# CY8C5888LTI_LP097 register map
File version: 0.1
Registers are 8-bit, read-write, no defined reset value unless marked. A register's access mark holds for its fields unless they carry their own. Offsets are from the block's base; [hi:lo] are bit positions; 'fields as' and 'values as' point back to an identical list.

## PWM_1
Base 0x00000000
0x4000642A PWM_1_COMPARE_Reg 16-bit — UDB.D0 - Assigned Compare Value
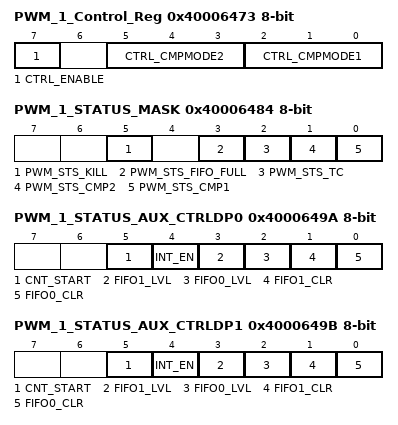
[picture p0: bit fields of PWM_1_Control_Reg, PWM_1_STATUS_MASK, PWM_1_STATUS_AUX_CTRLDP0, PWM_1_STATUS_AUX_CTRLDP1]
0x40006473 PWM_1_Control_Reg — UDB Control Register - Assigned Control Register Value
  [7] CTRL_ENABLE — Enable the PWM
  [5:3] CTRL_CMPMODE2 — Compare mode 2
  [2:0] CTRL_CMPMODE1 — Compare mode 1
0x40006484 PWM_1_STATUS_MASK — UDB Status bits Interrupt Mask Enable Register
  [5] PWM_STS_KILL ro — Enables the Interrupt on Kill
  [3] PWM_STS_FIFO_FULL ro — FIFO Full Status Mask
  [2] PWM_STS_TC ro — Enables the Interrupt on Terminal Count
  [1] PWM_STS_CMP2 ro — Enables the Interrupt on Compare 2
  [0] PWM_STS_CMP1 ro — Enables the Interrupt on Compare 1
0x4000649A PWM_1_STATUS_AUX_CTRLDP0 — UDB Auxilliary Control Register
  [5] CNT_START — FIFO0 clear
    0=E_CNT_START0 (Disable counter); 1=E_CNT_START1 (Enable counter)
  [4] INT_EN
    0=E_INT_EN0 (Interrupt disabled); 1=E_INT_EN1 (Interrupt enabled)
  [3] FIFO1_LVL — FIFO level
    0=E_FIFO_LVL_0 (FIFO LVL: input mode: FIFO not full; output mode: FIFO not empty); 1=E_FIFO_LVL_1 (FIFO LVL: input mode: FIFO at least 1/2 empty; output mode: FIFO at least 1/2 full)
  [2] FIFO0_LVL — FIFO level
    values as FIFO1_LVL
  [1] FIFO1_CLR — FIFO1 clear
    0=E_FIFO_CLR_0 (Normal FIFO operation); 1=E_FIFO_CLR_1 (Clear FIFO state)
  [0] FIFO0_CLR — FIFO0 clear
    values as FIFO1_CLR
0x4000649B PWM_1_STATUS_AUX_CTRLDP1 — UDB Auxilliary Control Register
  fields as PWM_1_STATUS_AUX_CTRLDP0

## PWM_2
Base 0x00000000
0x40006426 PWM_2_COMPARE_Reg 16-bit — UDB.D0 - Assigned Compare Value
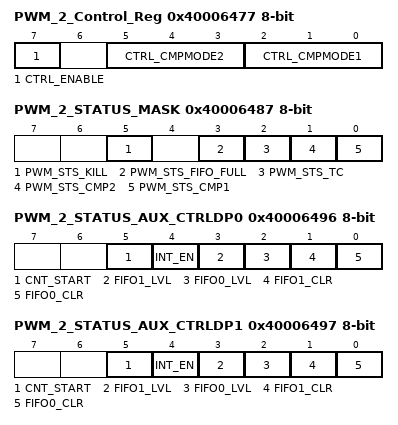
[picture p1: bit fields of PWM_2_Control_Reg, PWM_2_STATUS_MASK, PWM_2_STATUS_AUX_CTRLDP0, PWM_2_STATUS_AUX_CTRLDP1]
0x40006477 PWM_2_Control_Reg — UDB Control Register - Assigned Control Register Value
  [7] CTRL_ENABLE — Enable the PWM
  [5:3] CTRL_CMPMODE2 — Compare mode 2
  [2:0] CTRL_CMPMODE1 — Compare mode 1
0x40006487 PWM_2_STATUS_MASK — UDB Status bits Interrupt Mask Enable Register
  [5] PWM_STS_KILL ro — Enables the Interrupt on Kill
  [3] PWM_STS_FIFO_FULL ro — FIFO Full Status Mask
  [2] PWM_STS_TC ro — Enables the Interrupt on Terminal Count
  [1] PWM_STS_CMP2 ro — Enables the Interrupt on Compare 2
  [0] PWM_STS_CMP1 ro — Enables the Interrupt on Compare 1
0x40006496 PWM_2_STATUS_AUX_CTRLDP0 — UDB Auxilliary Control Register
  [5] CNT_START — FIFO0 clear
    0=E_CNT_START0 (Disable counter); 1=E_CNT_START1 (Enable counter)
  [4] INT_EN
    0=E_INT_EN0 (Interrupt disabled); 1=E_INT_EN1 (Interrupt enabled)
  [3] FIFO1_LVL — FIFO level
    0=E_FIFO_LVL_0 (FIFO LVL: input mode: FIFO not full; output mode: FIFO not empty); 1=E_FIFO_LVL_1 (FIFO LVL: input mode: FIFO at least 1/2 empty; output mode: FIFO at least 1/2 full)
  [2] FIFO0_LVL — FIFO level
    values as FIFO1_LVL
  [1] FIFO1_CLR — FIFO1 clear
    0=E_FIFO_CLR_0 (Normal FIFO operation); 1=E_FIFO_CLR_1 (Clear FIFO state)
  [0] FIFO0_CLR — FIFO0 clear
    values as FIFO1_CLR
0x40006497 PWM_2_STATUS_AUX_CTRLDP1 — UDB Auxilliary Control Register
  fields as PWM_2_STATUS_AUX_CTRLDP0

## SPI
Base 0x00000000
0x4000640D SPI_TX_DATA — SPIS TX Data
0x4000640D SPI_RX_DATA — SPIS RX Data
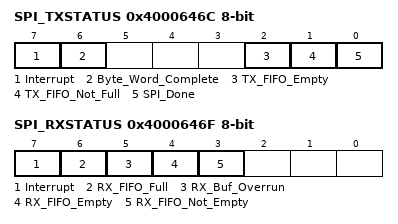
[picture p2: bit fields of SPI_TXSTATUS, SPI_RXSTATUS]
0x4000646C SPI_TXSTATUS — SPIS TX Status Register
  [7] Interrupt ro — Set when interrupt occurs
  [6] Byte_Word_Complete ro — Set when a byte/word transmit has completed
  [2] TX_FIFO_Empty ro — Set when the TX Data FIFO is empty
  [1] TX_FIFO_Not_Full ro — Set when the TX Data FIFO is not full
  [0] SPI_Done ro — Set when all of the data in the transmit FIFO has been sent. Set when Byte/Word Complete has been set and TX Data FIFO is empty
0x4000646F SPI_RXSTATUS — SPIS RX Status Register
  [7] Interrupt ro — Set when interrupt occurs
  [6] RX_FIFO_Full ro — Set when the RX Data FIFO is full
  [5] RX_Buf_Overrun ro — Set when RX Data has overrun the 4 byte/word FIFO without being moved to the RX buffer cmemory array (if one exists)
  [4] RX_FIFO_Empty ro — Set when the RX Data FIFO is empty
  [3] RX_FIFO_Not_Empty ro — Set when the RX Data FIFO is not empty. That is, at least one byte/word is in the RX FIFO
